# SPI register map
Vendor: Texas Instruments
Peripheral module from a debugger description file (folder CC26x4).
Registers are 32-bit, access not given, reset values left out (the file's numbers can be read two ways) unless marked. A register's access mark holds for its fields unless they carry their own. Offsets are as the file gives them; lines under a group give offsets from that group; [hi:lo] are bit positions; {n}, {i} and the like mark numbered series; 'fields as' and 'values as' point back to an identical list; <NAME> marks a mode.

## SPI — Serial Peripheral Interface (SPI) with master and slave capabilities
0x20 IIDX ro — This register provides the highest priority enabled interrupt index. Value 0x00 means no event pending. Interrupt 1 is the highest priority, and 31 is the least priority. That is, the least bit position that is set to 1 denotes the highest priority pending interrupt. The priority order is fixed. However, users can implement their own prioritization schemes using other registers that expose the full set of interrupts that have occurred. On each read, only one interrupt is indicated. On a read, the current interrupt (highest priority) is automatically cleared by the hardware and the corresponding interrupt flag in RIS and MIS are cleared as well. After a read from the CPU (not from the debug interface), the register is updated with the next highest priority interrupt, if none are pending, then it would display 0x0.
  [7:0] STAT — Interrupt index status
    9=DMA_DONE_TX_EVT (DMA Done for Transmit Event/interrupt pending); 8=DMA_DONE_RX_EVT (DMA Done for Receive Event/interrupt pending); 7=IDLE_EVT (End of Transmit Event/interrupt pending); 6=TX_EMPTY (Transmit Buffer Empty Event/interrupt pending); 5=TX_EVT (Transmit Event/interrupt pending); 4=RX_EVT (Receive Event/interrupt pending); 3=RTOUT_EVT (SPI Receive Time-Out Event/interrupt pending); 2=PER_EVT (Transmit Parity Event/interrupt pending); 1=RXFIFO_OFV_EVT (RX FIFO Overflow Event/interrupt pending); 0=NO_INTR (No interrupt pending)
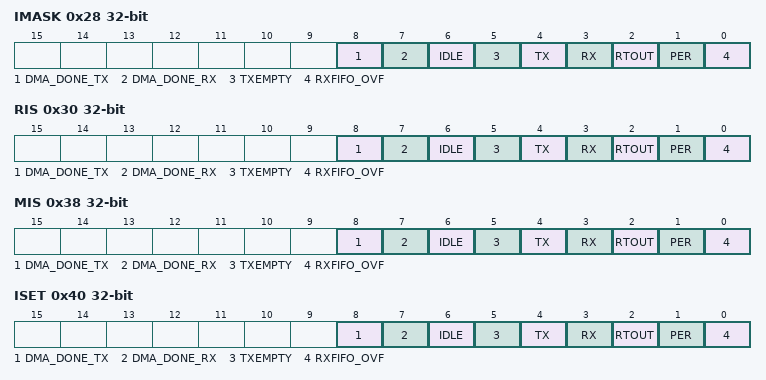
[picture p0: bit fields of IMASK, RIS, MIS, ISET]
0x28 IMASK — Interrupt Mask. If a bit is set, then corresponding interrupt is un-masked. Un-masking the interrupt causes the raw interrupt to be visible in IIDX, as well as MIS.
  [all] fields
    1=SET (Set Interrupt Mask); 0=CLR (Clear Interrupt Mask)
  [8] DMA_DONE_TX — DMA Done event for TX event mask.
  [7] DMA_DONE_RX — DMA Done event for RX event mask.
  [6] IDLE — SPI Idle event mask.
  [5] TXEMPTY — Transmit FIFO Empty event mask.
  [4] TX — Transmit FIFO event mask.
  [3] RX — Receive FIFO event. This interrupt is set if the selected Receive FIFO level has been reached
  [2] RTOUT — SPI Receive Time-Out event mask.
  [1] PER — Parity error event mask.
  [0] RXFIFO_OVF — RXFIFO overflow event mask.
0x30 RIS — Raw interrupt status. Reflects all pending interrupts, regardless of masking. The RIS register allows the user to implement a poll scheme. A flag set in this register can be cleared by writing 1 to the ICLR register bit even if the corresponding IMASK bit is not enabled.
  [all] fields
    1=SET (Interrupt occurred); 0=CLR (Interrupt did not occur)
  [8] DMA_DONE_TX — DMA Done event for TX. This interrupt is set if the TX DMA channel sends the DONE signal. This allows the handling of the DMA event inside the mapped peripheral.
  [7] DMA_DONE_RX — DMA Done event for RX. This interrupt is set if the RX DMA channel sends the DONE signal. This allows the handling of the DMA event inside the mapped peripheral.
  [6] IDLE — SPI has completed transfers and changed into IDLE mode. This bit is set when STAT.BUSY goes low.
  [5] TXEMPTY — Transmit FIFO Empty interrupt mask. This interrupt is set if all data in the Transmit FIFO have been move to the shift register.
  [4] TX — Transmit FIFO event. This interrupt is set if the selected Transmit FIFO level has been reached.
  [3] RX — Receive FIFO event. This interrupt is set if the selected Receive FIFO level has been reached
  [2] RTOUT — SPI Receive Time-Out event.
  [1] PER — Parity error event: this bit is set if a parity error has been detected
  [0] RXFIFO_OVF — RXFIFO overflow event. This interrupt is set if an RX FIFO overflow has been detected.
0x38 MIS — Masked interrupt status. This is an AND of the IMASK and RIS registers.
  [all] fields
    1=SET (Interrupt occurred); 0=CLR (Interrupt did not occur)
  [8] DMA_DONE_TX — Masked DMA Done event for TX.
  [7] DMA_DONE_RX — Masked DMA Done event for RX.
  [6] IDLE — Masked SPI IDLE mode event.
  [5] TXEMPTY — Masked Transmit FIFO Empty event.
  [4] TX — Masked Transmit FIFO event. This interrupt is set if the selected Transmit FIFO level has been reached.
  [3] RX — Masked receive FIFO event. This interrupt is set if the selected Receive FIFO level has been reached
  [2] RTOUT — Masked SPI Receive Time-Out Interrupt.
  [1] PER — Masked Parity error event: this bit if a parity error has been detected
  [0] RXFIFO_OVF — Masked RXFIFO overflow event. This interrupt is set if an RX FIFO overflow has been detected.
0x40 ISET — Interrupt set. Allows interrupts to be set by software (useful in diagnostics and safety checks). Writing a 1 to a bit in ISET will set the event and therefore the related RIS bit also gets set. If the interrupt is enabled through the mask, then the corresponding MIS bit is also set.
  [all] fields
    1=SET (Set Interrupt); 0=NO_EFFECT (Writing 0 has no effect)
  [8] DMA_DONE_TX — Set DMA Done event for TX.
  [7] DMA_DONE_RX — Set DMA Done event for RX.
  [6] IDLE — Set SPI IDLE mode event.
  [5] TXEMPTY — Set Transmit FIFO Empty event.
  [4] TX — Set Transmit FIFO event.
  [3] RX — Set Receive FIFO event.
  [2] RTOUT — Set SPI Receive Time-Out event.
  [1] PER — Set Parity error event.
  [0] RXFIFO_OVF — Set RXFIFO overflow event.
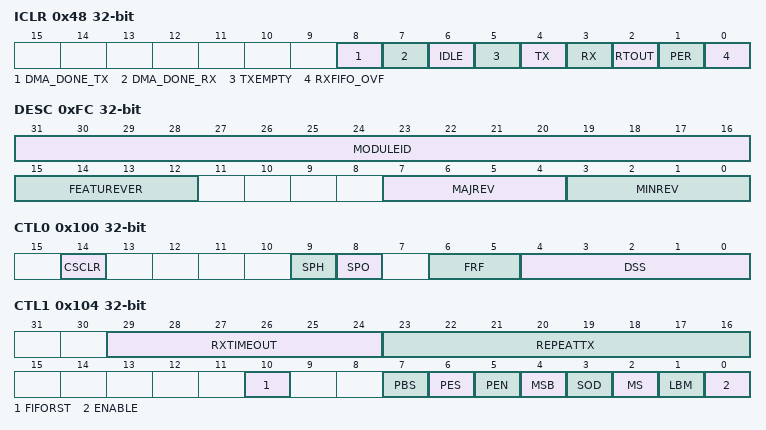
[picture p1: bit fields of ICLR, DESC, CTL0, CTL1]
0x48 ICLR — Interrupt clear. Write a 1 to clear the corresponding Interrupt.
  [all] fields
    1=CLR (Clear Interrupt); 0=NO_EFFECT (Writing 0 has no effect)
  [8] DMA_DONE_TX — Clear DMA Done event for TX.
  [7] DMA_DONE_RX — Clear DMA Done event for RX.
  [6] IDLE — Clear SPI IDLE mode event.
  [5] TXEMPTY — Clear Transmit FIFO Empty event.
  [4] TX — Clear Transmit FIFO event.
  [3] RX — Clear Receive FIFO event.
  [2] RTOUT — Clear SPI Receive Time-Out event.
  [1] PER — Clear Parity error event.
  [0] RXFIFO_OVF — Clear RXFIFO overflow event.
0xE0 EVT_MODE access per field — Event mode register. It is used to select whether each line is disabled, in software mode (software clears the RIS) or in hardware mode (hardware clears the RIS) Note: The recommendation is to use SPI in the software mode
  [1:0] INT0_CFG rw — Event line mode select for event corresponding to IPSTANDARD.INT_EVENT0
    2=HARDWARE (The interrupt or event line is in hardware mode. The hardware automatically clears the RIS flag.); 1=SOFTWARE (The interrupt or event line is in software mode. Software must clear the RIS.); 0=DISABLE (The interrupt or event line is disabled.)
0xFC DESC — This register identifies the peripheral and its exact version.
  [31:16] MODULEID — Module identification contains a unique peripheral identification number. The assignments are maintained in a central database for all of the platform modules to ensure uniqueness.
  [15:12] FEATUREVER — Feature set version for this module instance.
  [7:4] MAJREV — Major revision of the IP
  [3:0] MINREV — Minor revision of the IP
0x100 CTL0 access per field — SPI Control Register 0
  [14] CSCLR rw — Clear shift register counter when CS gets inactive. This bit is relevant only in the slave mode, CTL1.MS = 0.
    1=ENABLE (Enable automatic clear of shift register when CS gets inactive.); 0=DISABLE (Disable automatic clear of shift register when CS gets inactive.)
  [9] SPH rw — CLKOUT phase (Motorola SPI frame format only) This bit selects the clock edge that captures data and enables it to change state. It has the most impact on the first bit transmitted by either permitting or not permitting a clock transition before the first data capture edge.
    1=SECOND (Data is captured on the second clock edge transition.); 0=FIRST (Data is captured on the first clock edge transition.)
  [8] SPO rw — CLKOUT polarity (Motorola SPI frame format only)
    1=HIGH (SPI produces a steady state HIGH value on the CLKOUT when data is not being transferred.); 0=LOW (SPI produces a steady state LOW value on the CLKOUT when data is not being transferred.)
  [6:5] FRF rw — Frame format Select
    3=MIRCOWIRE (National MICROWIRE frame format); 2=TI_SYNC (TI synchronous serial frame format); 1=MOTOROLA_4WIRE (Motorola SPI frame format (4 wire mode)); 0=MOTOROLA_3WIRE (Motorola SPI frame format (3 wire mode))
  [4:0] DSS rw — Data Size Select. Note: Master mode: Values 0 - 2 are reserved and shall not be used. This will map to 4 bit mode. A value of 3h corresponds to 4-bit data (and so on). Slave mode: DSS should be no less than 6 which means the minimum frame length is 7 bits.
    {v}=Data Size Select bits: {v+1} (v=3..31)
0x104 CTL1 access per field — SPI Control Register 1
  [29:24] RXTIMEOUT rw — Receive Timeout (only for Slave mode). This register defines the number of clock cycles after which the Receive Timeout interrupt is set. A value of 0 disables this function.
    63=MAXIMUM (Highest possible value); 0=MINIMUM (Smallest value)
  [23:16] REPEATTX rw — Counter to repeat last transfer. A value of 0 disables this feature. After a non-zero value (X) is written to this register, SPI transfer can be started with writing a data into the TX Buffer. The data will be transferred X+1 times in total. The behavior is identical as if the data were be written into the TX Buffer that many times as defined by the value here additionally. It can be used to clean a transfer or to pull a certain amount of data by a slave. This feature can be used only in the master mode.
    0=DISABLE (REPEATTX disable)
  [10] FIFORST rw — This bit is used to reset transmit and receive FIFO pointers. The pointers are held at a reset value until this bit is cleared to zero.
    1=SET (Set FIFO pointers reset trigger); 0=CLR (Clear FIFO pointers reset trigger)
  [7] PBS rw — Parity Bit Select
    1=ENABLE (Bit 1 is used for Parity, Bit 0 is ignored); 0=DISABLE (Bit 0 is used for Parity)
  [6] PES rw — Even Parity Select
    1=ENABLE (Even Parity mode); 0=DISABLE (Odd Parity mode)
  [5] PEN rw — Parity enable if enabled the last bit will be used as parity to evaluate the right transmission of the previous bits. In case of a parity mismatch the parity error flag RIS.PER will be set.
    1=ENABLE (Enable Parity function); 0=DISABLE (Disable Parity function)
  [4] MSB rw — MSB first select. Controls the direction of the receive and transmit shift register.
    1=ENABLE (MSB first); 0=DISABLE (LSB first)
  [3] SOD rw — Slave-mode: Data output disabled This bit is relevant only in the slave mode, MS=0. In multiple-slave systems, it is possible for an SPI master to broadcast a message to all slaves in the system while ensuring that only one slave drives data onto its serial output line. In such systems the RX lines from multiple slaves could be tied together. To operate in such systems, this bitfield can be set if the SPI slave is not supposed to drive the TX line.
    1=ENABLE (SPI cannot drive the MISO output via TX in slave mode.); 0=DISABLE (SPI can drive the MISO output via TX in slave mode.)
  [2] MS rw — Master or slave mode select. This bit can be modified only when SPI is disabled, CTL1.ENABLE = 0.
    1=ENABLE (Select Master Mode); 0=DISABLE (Select Slave Mode)
  [1] LBM rw — Loop back mode
    1=ENABLE (Enable loopback mode.Output of transmit serial shifter is connected to input of receive serial shifter internally.); 0=DISABLE (Disable loopback mode. Normal serial port operation enabled.)
  [0] ENABLE rw — SPI enable
    1=ENABLE (Enable module function); 0=DISABLE (Disable module function)
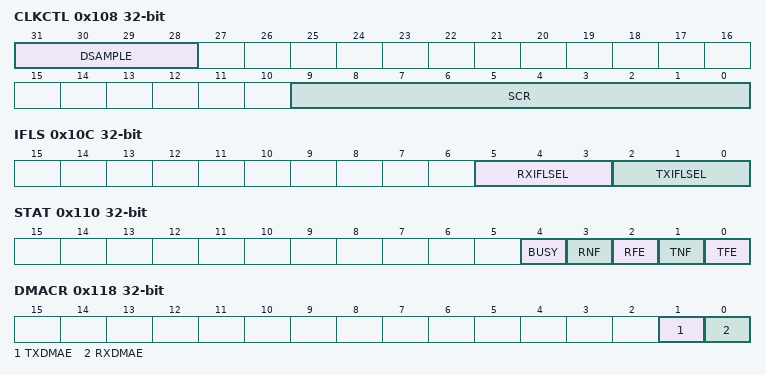
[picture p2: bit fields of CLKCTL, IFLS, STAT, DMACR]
0x108 CLKCTL access per field — Clock prescaler and divider register. This register contains the settings for the Clock prescaler and divider settings.
  [31:28] DSAMPLE rw — Delayed sampling. In master mode the data on the input pin will be sampled after the defined clock cycles. Note: As an example, if the SPI transmit frequency is set to 12 MHz in the master mode, DSAMPLE should be set to a value of 2
  [9:0] SCR rw — Serial clock divider: This is used to generate the transmit and receive bit rate of the SPI. The SPI bit rate is (SPI's functional clock frequency)/((SCR+1)*2). SCR is a value from 0-1023.
    0x3FF=MAXIMUM (Highest possible value); 0=MINIMUM (Smallest value)
0x10C IFLS access per field — The IFLS register is the interrupt FIFO level select register. This register can be used to define the levels at which the TX, RX FIFO interrupt flags are triggered. Out of reset, the TXIFLSEL and RXIFLSEL bits are configured so that the FIFOs trigger an interrupt at the half-way mark.
  [5:3] RXIFLSEL rw — SPI Receive Interrupt FIFO Level Select The trigger points for the receive interrupt are as follows:
    7=LEVEL_1 (Trigger when RX FIFO contains >= 1 byte); 6=LVL_RES6 (Reserved); 5=LVL_FULL (RX FIFO is full); 4=LVL_RES4 (Reserved); 3=LVL_3_4 (RX FIFO >= 3/4 full); 2=LVL_1_2 (RX FIFO >= 1/2 full (default)); 1=LVL_1_4 (RX FIFO >= 1/4 full); 0=LVL_OFF (Reserved)
  [2:0] TXIFLSEL rw — SPI Transmit Interrupt FIFO Level Select The trigger points for the transmit interrupt are as follows:
    7=LEVEL_1 (Trigger when TX FIFO has >= 1 byte free); 6=LVL_RES6 (Reserved); 5=LVL_EMPTY (TX FIFO is empty); 4=LVL_RES4 (Reserved); 3=LVL_1_4 (TX FIFO <= 1/4 empty); 2=LVL_1_2 (TX FIFO <= 1/2 empty (default)); 1=LVL_3_4 (TX FIFO <= 3/4 empty); 0=LVL_OFF (Reserved)
0x110 STAT — Status Register
  [4] BUSY
    1=ACTIVE (SPI is currently transmitting and/or receiving data, or transmit FIFO is not empty.); 0=IDLE (SPI is in idle mode.)
  [3] RNF — Receive FIFO not full
    1=NOT_FULL (Receive FIFO is not full.); 0=FULL (Receive FIFO is full.)
  [2] RFE — Receive FIFO empty.
    1=EMPTY (Receive FIFO is empty.); 0=NOT_EMPTY (Receive FIFO is not empty.)
  [1] TNF — Transmit FIFO not full
    1=NOT_FULL (Transmit FIFO is not full.); 0=FULL (Transmit FIFO is full.)
  [0] TFE — Transmit FIFO empty.
    1=EMPTY (Transmit FIFO is empty.); 0=NOT_EMPTY (Transmit FIFO is not empty.)
0x114 CLKDIV2 access per field — This register is used to specify a divide ratio of the SPI functional clock.
  [2:0] RATIO rw — Selects divide ratio of module clock
    {v}=DIV_BY_{v+1} (Divide clock source by {v+1}) (v=1..7); 0=DIV_BY_1 (Do not divide clock source)
0x118 DMACR access per field — DMA Control Register
  [1] TXDMAE rw — Transmit FIFO DMA enable when set.
  [0] RXDMAE rw — Receive FIFO DMA enable when set.
0x130 RXDATA ro — RXDATA Register. Reading this register returns value in the RX FIFO pointed by the current FIFO read pointer. If the RX FIFO is empty, the last read value is returned. Writing has not effect and is ignored.
  [31:0] DATA — Received Data
0x140 TXDATA rw — TXDATA Register. Writing into this register puts the data into the TX FIFO. Reading this register returns the last written value, pointed by the current FIFO write pointer.
  [31:0] DATA — Transmit Data
